# ATSAM4LC2C device description
Architecture: CORTEX-M4; Family: SAM4; Series: SAM4L
Registers are 32-bit, read-write, reset 0x0 unless marked. A register's access mark holds for its fields unless they carry their own. Offsets are from the block's base; [hi:lo] are bit positions; lines under a group give offsets from that group; {n}, {i} and the like mark numbered series; 'fields as' and 'values as' point back to an identical list.

## HMATRIXB — HSB Matrix
Instances: HMATRIX 0x400A1000
{0x0+4i} MCFG[{i}] (i=0..15) reset 0x2 — Master Configuration Register
  [2:0] ULBT — Undefined Length Burst Type
    0=INFINITE (Infinite Length); 1=SINGLE (Single Access); 2=FOUR_BEAT (Four Beat Burst); 3=EIGHT_BEAT (Eight Beat Burst); 4=SIXTEEN_BEAT (Sixteen Beat Burst)
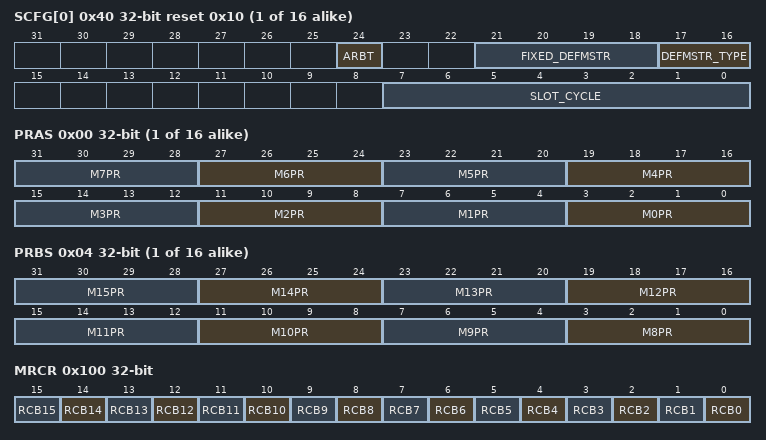
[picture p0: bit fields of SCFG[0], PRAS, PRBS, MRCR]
{0x40+4i} SCFG[{i}] (i=0..15) reset 0x10 — Slave Configuration Register
  [24] ARBT — Arbitration Type
    0=ROUND_ROBIN (Round-Robin Arbitration); 1=FIXED_PRIORITY (Fixed Priority Arbitration)
  [21:18] FIXED_DEFMSTR — Fixed Index of Default Master
  [17:16] DEFMSTR_TYPE — Default Master Type
    0=NO_DEFAULT (No Default Master. At the end of current slave access, if no other master request is pending, the slave is deconnected from all masters. This resusts in having a one cycle latency for the first transfer of a burst.); 1=LAST_DEFAULT (Last Default Master At the end of current slave access, if no other master request is pending, the slave stay connected with the last master havingaccessed it.This resusts in not having the one cycle latency when the last master re-trying access on the slave.); 2=FIXED_DEFAULT (Fixed Default Master At the end of current slave access, if no other master request is pending, the slave connects with fixed master which numberis in FIXED_DEFMSTR register.This resusts in not having the one cycle latency when the fixed master re-trying access on the slave.)
  [7:0] SLOT_CYCLE — Maximum Number of Allowed Cycles for a Burst
{0x80+8i} prs[{i}] (i=0..15) group
  0x00 PRAS — Priority Register A for Slave
    [4n+3:4n] M{n}PR (n=0..7) — Master {n} Priority
  0x04 PRBS — Priority Register B for Slave
    [4n-29:4n-32] M{n}PR (n=8..15) — Master {n} Priority
0x100 MRCR — Master Remap Control Register
  [all] fields
    0=Disable remapped address decoding for master; 1=Enable remapped address decoding for master
  [n] RCB{n} (n=0..15) — Remap Command bit for Master {n}
{0x110+4i} SFR[{i}] (i=0..15) — Special Function Register

## LCDCA — LCD Controller
Instances: LCDCA 0x40080000
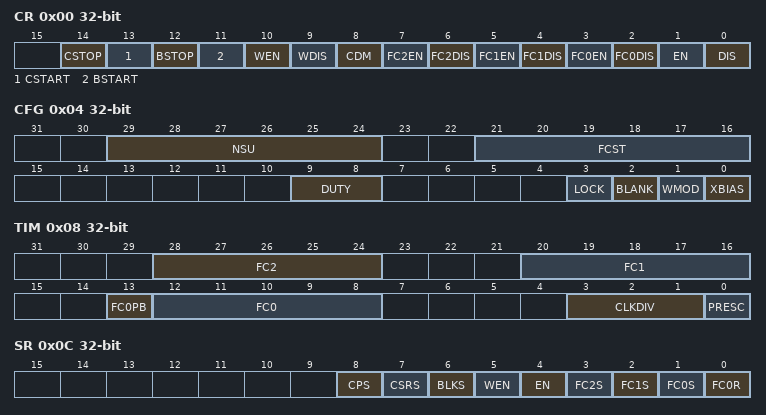
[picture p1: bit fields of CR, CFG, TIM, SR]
0x00 CR wo — Control Register
  [14] CSTOP — Circular Shift Stop
  [13] CSTART — Circular Shift Start
  [12] BSTOP — Blinking Stop
  [11] BSTART — Blinking Start
  [10] WEN — Wake up Enable
  [9] WDIS — Wake up Disable
  [8] CDM — Clear Display Memory
  [7] FC2EN — Frame Counter 2 Enable
  [6] FC2DIS — Frame Counter 2 Disable
  [5] FC1EN — Frame Counter 1 Enable
  [4] FC1DIS — Frame Counter 1 Disable
  [3] FC0EN — Frame Counter 0 Enable
  [2] FC0DIS — Frame Counter 0 Disable
  [1] EN — Enable
  [0] DIS — Disable
0x04 CFG — Configuration Register
  [29:24] NSU — Number of Segment Terminals in Use
  [21:16] FCST — Fine Contrast
  [9:8] DUTY — Duty Select
  [3] LOCK
  [2] BLANK — Blank LCD
  [1] WMOD — Waveform Mode
  [0] XBIAS — External Bias Generation
0x08 TIM — Timing Register
  [28:24] FC2 — Frame Counter 2
  [20:16] FC1 — Frame Counter 1
  [13] FC0PB — Frame Counter 0 Prescaler Bypass
  [12:8] FC0 — Frame Counter 0
  [3:1] CLKDIV — LCD Clock Division
  [0] PRESC — LCD Prescaler Select
0x0C SR ro — Status Register
  [8] CPS — Charge Pump Status
  [7] CSRS — Circular Shift Register Status
  [6] BLKS — Blink Status
  [5] WEN — Wake up Status
  [4] EN — LCDCA Status
  [3] FC2S — Frame Counter 2 Status
  [2] FC1S — Frame Counter 1 Status
  [1] FC0S — Frame Counter 0 Status
  [0] FC0R — Frame Counter 0 Rollover
0x10 SCR wo (atomic clear of SR) — Status Clear Register
  [0] FC0R — Frame Counter 0 Rollover
{0x14+8i} DRL{i} (i=0..3) — Data Register Low {i}
  [31:0] DATA — Segments Value
{0x18+8i} DRH{i} (i=0..3) — Data Register High {i}
  [7:0] DATA — Segments Value
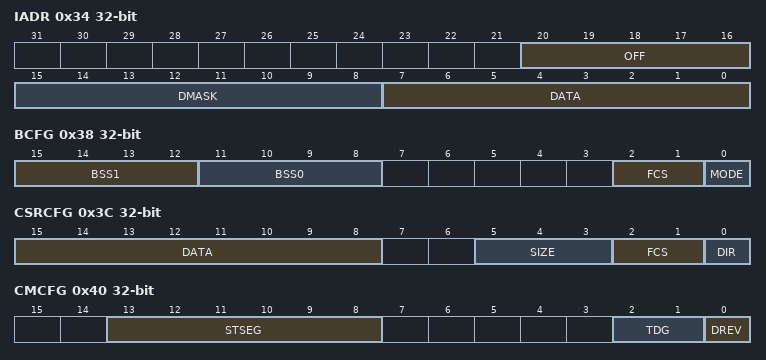
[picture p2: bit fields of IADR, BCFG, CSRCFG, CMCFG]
0x34 IADR wo — Indirect Access Data Register
  [20:16] OFF — Byte Offset
  [15:8] DMASK — Data Mask
  [7:0] DATA — Segments Value
0x38 BCFG — Blink Configuration Register
  [15:12] BSS1 — Blink Segment Selection 1
  [11:8] BSS0 — Blink Segment Selection 0
  [2:1] FCS — Frame Counter Selection
  [0] MODE — Blinking Mode
0x3C CSRCFG — Circular Shift Register Configuration
  [15:8] DATA — Circular Shift Register Value
  [5:3] SIZE
  [2:1] FCS — Frame Counter Selection
  [0] DIR — Direction
0x40 CMCFG — Character Mapping Configuration Register
  [13:8] STSEG — Start Segment
  [2:1] TDG — Type of Digit
  [0] DREV — Digit Reverse Mode
0x44 CMDR wo — Character Mapping Data Register
  [6:0] ASCII — ASCII Code
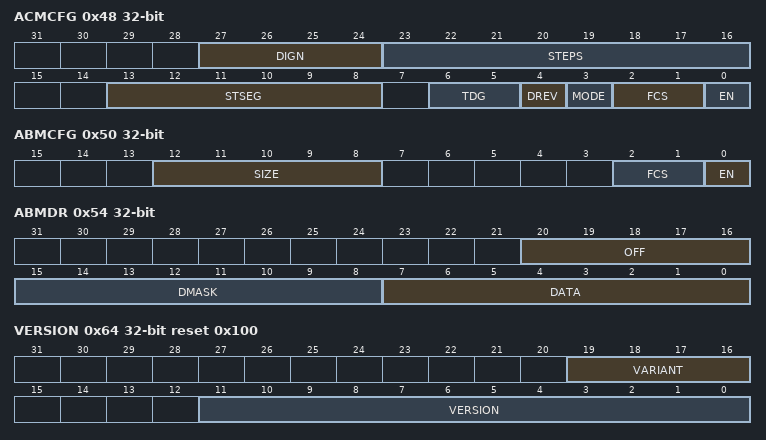
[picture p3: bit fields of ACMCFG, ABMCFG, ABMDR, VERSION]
0x48 ACMCFG — Automated Character Mapping Configuration Register
  [27:24] DIGN — Digit Number
  [23:16] STEPS — Scrolling Steps
  [13:8] STSEG — Start Segment
  [6:5] TDG — Type of Digit
  [4] DREV — Digit Reverse
  [3] MODE — Mode (sequential or scrolling)
  [2:1] FCS — Frame Counter Selection
  [0] EN — Enable
0x4C ACMDR wo — Automated Character Mapping Data Register
  [6:0] ASCII — ASCII Code
0x50 ABMCFG — Automated Bit Mapping Configuration Register
  [12:8] SIZE
  [2:1] FCS — Frame Counter Selection
  [0] EN — Enable
0x54 ABMDR wo — Automated Bit Mapping Data Register
  fields as IADR
0x58 IER wo (atomic set of IMR) — Interrupt Enable Register
  [0] FC0R — Frame Counter 0 Rollover
0x5C IDR wo (atomic clear of IMR) — Interrupt Disable Register
  [0] FC0R — Frame Counter 0 Rollover
0x60 IMR ro — Interrupt Mask Register
  [0] FC0R — Frame Counter 0 Rollover
0x64 VERSION ro reset 0x100
  [19:16] VARIANT — Variant Number
  [11:0] VERSION — Version Number

## Notices in the file
Copyright (c) 2016 Atmel Corporation,
a wholly owned subsidiary of Microchip Technology Inc.
Licensed under the Apache License, Version 2.0 (the "License");
you may not use this file except in compliance with the License.
You may obtain a copy of the Licence at
http://www.apache.org/licenses/LICENSE-2.0
Unless required by applicable law or agreed to in writing, software
distributed under the License is distributed on an "AS IS" BASIS,
WITHOUT WARRANTIES OR CONDITIONS OF ANY KIND, either express or implied.
See the License for the specific language governing permissions and
limitations under the License.
